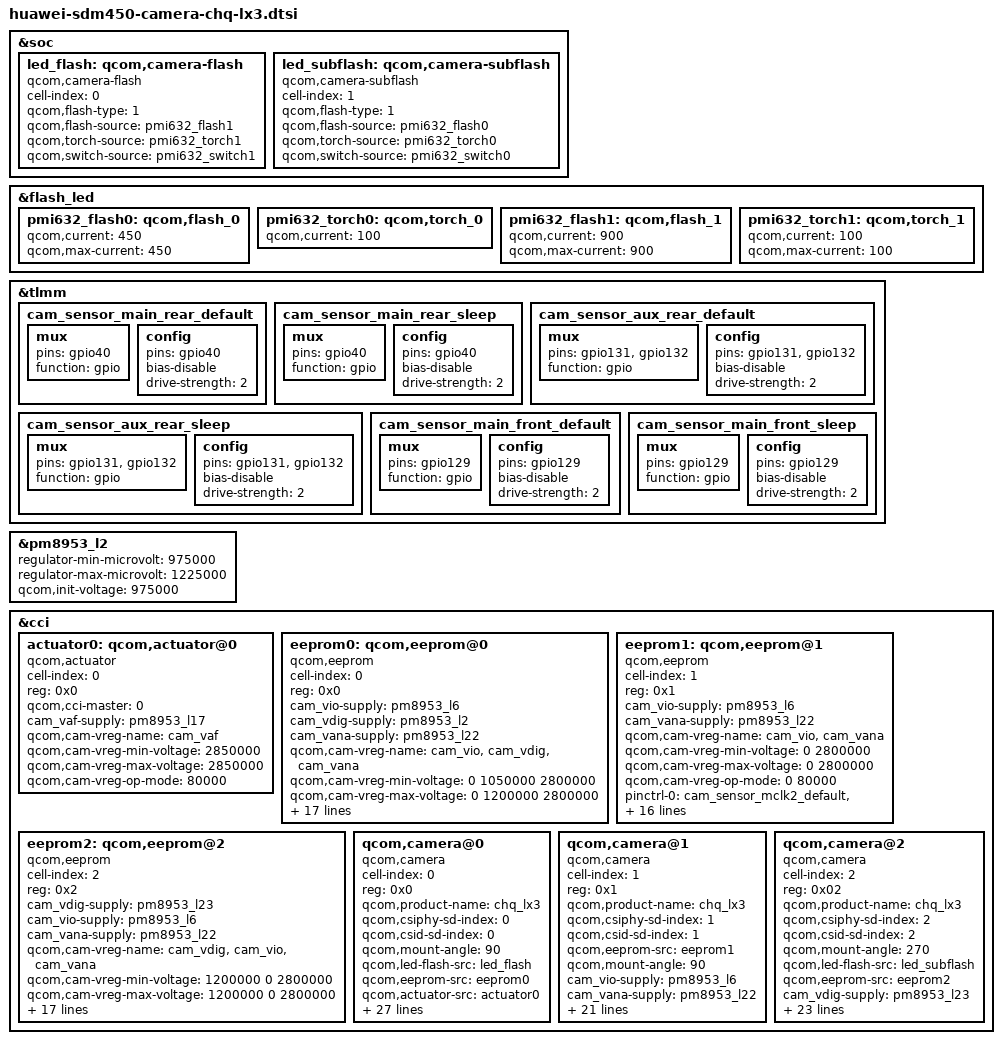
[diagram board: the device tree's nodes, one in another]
/*
 * Copyright (c) 2015-2018, The Linux Foundation. All rights reserved.
 *
 * This program is free software; you can redistribute it and/or modify
 * it under the terms of the GNU General Public License version 2 and
 * only version 2 as published by the Free Software Foundation.
 *
 * This program is distributed in the hope that it will be useful,
 * but WITHOUT ANY WARRANTY; without even the implied warranty of
 * MERCHANTABILITY or FITNESS FOR A PARTICULAR PURPOSE.  See the
 * GNU General Public License for more details.
 */
&soc {
	led_flash: qcom,camera-flash {//Back camera flash
		cell-index = <0>;
		compatible = "qcom,camera-flash";
		qcom,flash-type = <1>;
		qcom,flash-source = <&pmi632_flash1>;
		qcom,torch-source = <&pmi632_torch1>;
		qcom,switch-source = <&pmi632_switch1>;
	};

	led_subflash: qcom,camera-subflash {//Front camera flash
		cell-index = <1>;
		compatible = "qcom,camera-subflash";
		qcom,flash-type = <1>;
		qcom,flash-source = <&pmi632_flash0>;
		qcom,torch-source = <&pmi632_torch0>;
		qcom,switch-source = <&pmi632_switch0>;
	};
};

&flash_led {
	pmi632_flash0: qcom,flash_0 {
		qcom,current = <450>;
		qcom,max-current = <450>;
	};
	pmi632_torch0: qcom,torch_0 {
		qcom,current = <100>;
	};

	pmi632_flash1: qcom,flash_1 {
		qcom,current = <900>;
		qcom,max-current = <900>;
	};
	pmi632_torch1: qcom,torch_1 {
		qcom,current = <100>;
		qcom,max-current = <100>;
	};
};

&tlmm {
	cam_sensor_main_rear_default: cam_sensor_main_rear_default {
		/* RESET, STANDBY */
		mux {
			pins = "gpio40";
			function = "gpio";
		};

		config {
			pins = "gpio40";
			bias-disable; /* No PULL */
			drive-strength = <2>; /* 2 MA */
		};
	};

	cam_sensor_main_rear_sleep: cam_sensor_main_rear_sleep {
		/* RESET, STANDBY */
		mux {
			pins = "gpio40";
			function = "gpio";
		};

		config {
			pins = "gpio40";
			bias-disable; /* No PULL */
			drive-strength = <2>; /* 2 MA */
		};
	};

	cam_sensor_aux_rear_default: cam_sensor_aux_rear_default {
		/* RESET, STANDBY */
		mux {
			pins = "gpio131","gpio132";
			function = "gpio";
		};

		config {
			pins = "gpio131","gpio132";
			bias-disable; /* No PULL */
			drive-strength = <2>; /* 2 MA */
		};
	};

	cam_sensor_aux_rear_sleep: cam_sensor_aux_rear_sleep {
		/* RESET, STANDBY */
		mux {
			pins = "gpio131","gpio132";
			function = "gpio";
		};

		config {
			pins = "gpio131","gpio132";
			bias-disable; /* No PULL */
			drive-strength = <2>; /* 2 MA */
		};
	};

	cam_sensor_main_front_default: cam_sensor_main_front_default {
		/* RESET, STANDBY */
		mux {
			pins = "gpio129";
			function = "gpio";
		};

		config {
			pins = "gpio129";
			bias-disable; /* No PULL */
			drive-strength = <2>; /* 2 MA */
		};
	};

	cam_sensor_main_front_sleep: cam_sensor_main_front_sleep {
		/* RESET, STANDBY */
		mux {
			pins = "gpio129";
			function = "gpio";
		};

		config {
			pins = "gpio129";
			bias-disable; /* No PULL */
			drive-strength = <2>; /* 2 MA */
		};
	};

};

&pm8953_l2 {
        regulator-min-microvolt = <975000>;
        regulator-max-microvolt = <1225000>;
        qcom,init-voltage = <975000>;
};

&cci {
	/delete-node/ qcom,actuator@0;
	actuator0: qcom,actuator@0 {
		cell-index = <0>;
		reg = <0x0>;
		compatible = "qcom,actuator";
		qcom,cci-master = <0>;
		cam_vaf-supply = <&pm8953_l17>;
		qcom,cam-vreg-name = "cam_vaf";
		qcom,cam-vreg-min-voltage = <2850000>;
		qcom,cam-vreg-max-voltage = <2850000>;
		qcom,cam-vreg-op-mode = <80000>;
	};

	/delete-node/ qcom,eeprom@0;
	eeprom0: qcom,eeprom@0 {
		cell-index = <0>;
		compatible = "qcom,eeprom";
		reg = <0x0>;
		cam_vio-supply = <&pm8953_l6>;
		cam_vdig-supply = <&pm8953_l2>;
		cam_vana-supply = <&pm8953_l22>;
		qcom,cam-vreg-name = "cam_vio", "cam_vdig","cam_vana";
		qcom,cam-vreg-min-voltage = <0 1050000 2800000>;
		qcom,cam-vreg-max-voltage = <0 1200000 2800000>;
		qcom,cam-vreg-op-mode = <0 105000 80000>;
		pinctrl-names = "cam_default", "cam_suspend";
		pinctrl-0 = <&cam_sensor_mclk0_default
					&cam_sensor_main_rear_default>;
		pinctrl-1 = <&cam_sensor_mclk0_sleep
					&cam_sensor_main_rear_sleep>;
		gpios = <&tlmm 26 0>,
				<&tlmm 40 0>;
		qcom,gpio-reset = <1>;
		qcom,gpio-req-tbl-num = <0 1>;
		qcom,gpio-req-tbl-flags = <1 0>;
		qcom,gpio-req-tbl-label = "CAMIF_MCLK0",
					"CAM_RESET0";
		qcom,sensor-position = <0>;
		qcom,sensor-mode = <0>;
		qcom,cci-master = <0>;
		status = "ok";
		clocks = <&clock_gcc clk_mclk0_clk_src>,
				<&clock_gcc clk_gcc_camss_mclk0_clk>;
		clock-names = "cam_src_clk", "cam_clk";
		qcom,clock-rates = <24000000 0>;
	};

	/delete-node/ qcom,eeprom@1;
	eeprom1: qcom,eeprom@1 {
		cell-index = <1>;
		compatible = "qcom,eeprom";
		reg = <0x1>;
		cam_vio-supply = <&pm8953_l6>;
		cam_vana-supply = <&pm8953_l22>;
		qcom,cam-vreg-name = "cam_vio", "cam_vana";
		qcom,cam-vreg-min-voltage = <0 2800000>;
		qcom,cam-vreg-max-voltage = <0 2800000>;
		qcom,cam-vreg-op-mode = <0 80000>;
		pinctrl-names = "cam_default", "cam_suspend";
		pinctrl-0 = <&cam_sensor_mclk2_default
				&cam_sensor_aux_rear_default>;
		pinctrl-1 = <&cam_sensor_mclk2_sleep
				&cam_sensor_aux_rear_sleep>;
		gpios = <&tlmm 28 0>,
			    <&tlmm 131 0>,
			    <&tlmm 132 0>;
		qcom,gpio-reset = <1>;
		qcom,gpio-standby = <2>;
		qcom,gpio-req-tbl-num = <0 1 2>;
		qcom,gpio-req-tbl-flags = <1 0 0>;
		qcom,gpio-req-tbl-label = "CAMIF_MCLK1",
					"CAM_RESET1",
					"CAM_STANDBY1";
		qcom,sensor-position = <0>;
		qcom,sensor-mode = <0>;
		qcom,cci-master = <1>;
		status = "ok";
		clocks = <&clock_gcc clk_mclk2_clk_src>,
				<&clock_gcc clk_gcc_camss_mclk2_clk>;
		clock-names = "cam_src_clk", "cam_clk";
		qcom,clock-rates = <24000000 0>;
	};

	/delete-node/ qcom,eeprom@2;
	eeprom2: qcom,eeprom@2 {
		cell-index = <2>;
		reg = <0x2>;
		compatible = "qcom,eeprom";
		cam_vdig-supply = <&pm8953_l23>;
		cam_vio-supply = <&pm8953_l6>;
		cam_vana-supply = <&pm8953_l22>;
		qcom,cam-vreg-name = "cam_vdig", "cam_vio", "cam_vana";
		qcom,cam-vreg-min-voltage = <1200000 0 2800000>;
		qcom,cam-vreg-max-voltage = <1200000 0 2800000>;
		qcom,cam-vreg-op-mode = <105000 0 80000>;
		pinctrl-names = "cam_default", "cam_suspend";
		pinctrl-0 = <&cam_sensor_mclk1_default
				&cam_sensor_main_front_default>;
		pinctrl-1 = <&cam_sensor_mclk1_sleep
				&cam_sensor_main_front_sleep>;
		gpios = <&tlmm 27 0>,
			    <&tlmm 129 0>;
		qcom,gpio-reset = <1>;
		qcom,gpio-req-tbl-num = <0 1>;
		qcom,gpio-req-tbl-flags = <1 0>;
		qcom,gpio-req-tbl-label = "CAMIF_MCLK2",
					  "CAM_RESET2";
		qcom,sensor-position = <1>;
		qcom,sensor-mode = <0>;
		qcom,cci-master = <1>;
		status = "ok";
		clocks = <&clock_gcc clk_mclk1_clk_src>,
			<&clock_gcc clk_gcc_camss_mclk1_clk>;
		clock-names = "cam_src_clk", "cam_clk";
		qcom,clock-rates = <24000000 0>;
	};

	/delete-node/ qcom,camera@0;
	qcom,camera@0 {
		cell-index = <0>;
		compatible = "qcom,camera";
		reg = <0x0>;
		qcom,product-name = "chq_lx3";
		qcom,csiphy-sd-index = <0>;
		qcom,csid-sd-index = <0>;
		qcom,mount-angle = <90>;
		qcom,led-flash-src = <&led_flash>;
		qcom,eeprom-src = <&eeprom0>;
		qcom,actuator-src = <&actuator0>;
		cam_vio-supply = <&pm8953_l6>;
		cam_vdig-supply = <&pm8953_l2>;
		cam_vaf-supply = <&pm8953_l17>;
		cam_vana-supply = <&pm8953_l22>;
		qcom,cam-vreg-name = "cam_vio", "cam_vdig", "cam_vaf", "cam_vana";
		qcom,cam-vreg-min-voltage = <0 1050000 2850000 2800000>;
		qcom,cam-vreg-max-voltage = <0 1200000 2850000 2800000>;
		qcom,cam-vreg-op-mode = <0 105000 100000 80000>;
		pinctrl-names = "cam_default", "cam_suspend";
		pinctrl-0 = <&cam_sensor_mclk0_default
				&cam_sensor_main_rear_default>;
		pinctrl-1 = <&cam_sensor_mclk0_sleep &cam_sensor_main_rear_sleep>;
		gpios = <&tlmm 26 0>,
			<&tlmm 40 0>;
		qcom,gpio-reset = <1>;
		qcom,gpio-req-tbl-num = <0 1>;
		qcom,gpio-req-tbl-flags = <1 0>;
		qcom,gpio-req-tbl-label = "CAMIF_MCLK0",
			"CAM_RESET0";
		qcom,sensor-position = <0>;
		qcom,sensor-mode = <0>;
		qcom,cci-master = <0>;
		status = "ok";
		clocks = <&clock_gcc clk_mclk0_clk_src>,
				<&clock_gcc clk_gcc_camss_mclk0_clk>;
		clock-names = "cam_src_clk", "cam_clk";
		qcom,clock-rates = <24000000 0>;
	};

	/delete-node/ qcom,camera@1;
	qcom,camera@1 {
		cell-index = <1>;
		compatible = "qcom,camera";
		reg = <0x1>;
		qcom,product-name = "chq_lx3";
		qcom,csiphy-sd-index = <1>;
		qcom,csid-sd-index = <1>;
		qcom,eeprom-src = <&eeprom1>;
		qcom,mount-angle = <90>;
		cam_vio-supply = <&pm8953_l6>;
		cam_vana-supply = <&pm8953_l22>;
		qcom,cam-vreg-name = "cam_vio", "cam_vana";
		qcom,cam-vreg-min-voltage = <0 2800000>;
		qcom,cam-vreg-max-voltage = <0 2800000>;
		qcom,cam-vreg-op-mode = <0 80000>;
		pinctrl-names = "cam_default", "cam_suspend";
		pinctrl-0 = <&cam_sensor_mclk2_default
				&cam_sensor_aux_rear_default>;
		pinctrl-1 = <&cam_sensor_mclk2_sleep
				&cam_sensor_aux_rear_sleep>;
		gpios = <&tlmm 28 0>,
			<&tlmm 131 0>,
			<&tlmm 132 0>;
		qcom,gpio-reset = <1>;
		qcom,gpio-standby = <2>;
		qcom,gpio-req-tbl-num = <0 1 2>;
		qcom,gpio-req-tbl-flags = <1 0 0>;
		qcom,gpio-req-tbl-label = "CAMIF_MCLK1",
			"CAM_RESET1",
			"CAM_STANDBY1";
		qcom,sensor-position = <0>;
		qcom,sensor-mode = <0>;
		qcom,cci-master = <1>;
		status = "ok";
		clocks = <&clock_gcc clk_mclk2_clk_src>,
				<&clock_gcc clk_gcc_camss_mclk2_clk>;
		clock-names = "cam_src_clk", "cam_clk";
		qcom,clock-rates = <24000000 0>;
	};

	/delete-node/ qcom,camera@2;
	qcom,camera@2 {
		cell-index = <2>;
		compatible = "qcom,camera";
		reg = <0x02>;
		qcom,product-name = "chq_lx3";
		qcom,csiphy-sd-index = <2>;
		qcom,csid-sd-index = <2>;
		qcom,mount-angle = <270>;
		qcom,led-flash-src = <&led_subflash>;
		qcom,eeprom-src = <&eeprom2>;
		cam_vdig-supply = <&pm8953_l23>;
		cam_vio-supply = <&pm8953_l6>;
		cam_vana-supply = <&pm8953_l22>;
		qcom,cam-vreg-name = "cam_vdig", "cam_vio", "cam_vana";
		qcom,cam-vreg-min-voltage = <1200000 0 2800000>;
		qcom,cam-vreg-max-voltage = <1200000 0 2800000>;
		qcom,cam-vreg-op-mode = <105000 0 80000>;
		pinctrl-names = "cam_default", "cam_suspend";
		pinctrl-0 = <&cam_sensor_mclk1_default
				&cam_sensor_main_front_default>;
		pinctrl-1 = <&cam_sensor_mclk1_sleep
				&cam_sensor_main_front_sleep>;
		gpios = <&tlmm 27 0>,
			<&tlmm 129 0>;
		qcom,gpio-reset = <1>;
		qcom,gpio-req-tbl-num = <0 1>;
		qcom,gpio-req-tbl-flags = <1 0>;
		qcom,gpio-req-tbl-label = "CAMIF_MCLK2",
					  "CAM_RESET2";
		qcom,sensor-position = <1>;
		qcom,sensor-mode = <0>;
		qcom,cci-master = <1>;
		status = "ok";
		clocks = <&clock_gcc clk_mclk1_clk_src>,
			<&clock_gcc clk_gcc_camss_mclk1_clk>;
		clock-names = "cam_src_clk", "cam_clk";
		qcom,clock-rates = <24000000 0>;
	};
};
